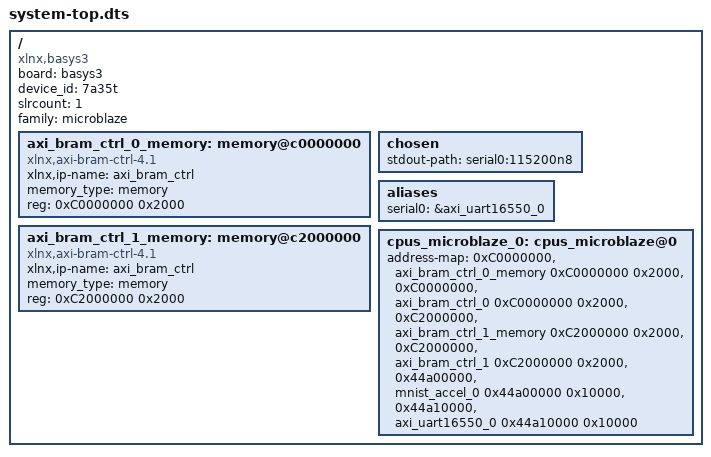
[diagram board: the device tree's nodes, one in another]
/dts-v1/;
#include "pl.dtsi"
/ {
	board = "basys3";
	compatible = "xlnx,basys3";
	device_id = "7a35t";
	#address-cells = <1>;
	#size-cells = <1>;
	slrcount = <1>;
	family = "microblaze";
	axi_bram_ctrl_0_memory: memory@c0000000 {
		compatible = "xlnx,axi-bram-ctrl-4.1";
		xlnx,ip-name = "axi_bram_ctrl";
		device_type = "memory";
		memory_type = "memory";
		reg = <0xC0000000 0x2000>;
	};
	axi_bram_ctrl_1_memory: memory@c2000000 {
		compatible = "xlnx,axi-bram-ctrl-4.1";
		xlnx,ip-name = "axi_bram_ctrl";
		device_type = "memory";
		memory_type = "memory";
		reg = <0xC2000000 0x2000>;
	};
	chosen {
		stdout-path = "serial0:115200n8";
	};
	aliases {
		serial0 = &axi_uart16550_0;
	};
	cpus_microblaze_0: cpus_microblaze@0 {
		address-map = <0xC0000000 &axi_bram_ctrl_0_memory 0xC0000000 0x2000>, 
			      <0xC0000000 &axi_bram_ctrl_0 0xC0000000 0x2000>, 
			      <0xC2000000 &axi_bram_ctrl_1_memory 0xC2000000 0x2000>, 
			      <0xC2000000 &axi_bram_ctrl_1 0xC2000000 0x2000>, 
			      <0x44a00000 &mnist_accel_0 0x44a00000 0x10000>, 
			      <0x44a10000 &axi_uart16550_0 0x44a10000 0x10000>;
		#ranges-address-cells = <0x1>;
		#ranges-size-cells = <0x1>;
	};
};
